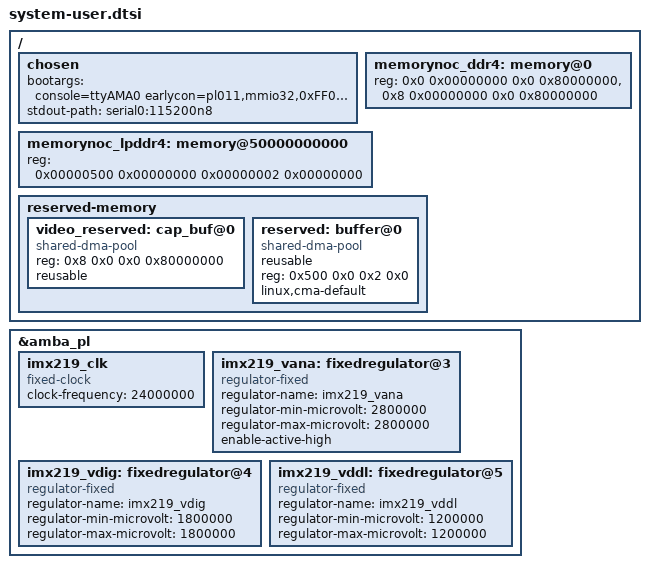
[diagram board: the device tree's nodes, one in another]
//#include <dt-bindings/media/xilinx-vip.h>
/include/ "system-conf.dtsi"
/ {
	chosen {
		//bootargs = "console=ttyAMA0  earlycon=pl011,mmio32,0xFF000000,115200n8 clk_ignore_unused root=/dev/mmcblk0p2 rw rootwait";	
		//bootargs = "console=ttyAMA0  earlycon=pl011,mmio32,0xFF000000,115200n8 clk_ignore_unused debug root=/dev/mmcblk0p2 rw rootwait";
		//bootargs = "console=ttyAMA0  earlycon=pl011,mmio32,0xFF000000,115200n8 clk_ignore_unused dyndbg=\"QUERY\" root=/dev/mmcblk0p2 rw rootwait";
		bootargs = "console=ttyAMA0  earlycon=pl011,mmio32,0xFF000000,115200n8 clk_ignore_unused dyndbg=\"file drivers/gpu/drm/xlnx/* +p\" root=/dev/mmcblk0p2 rw rootwait";
		stdout-path = "serial0:115200n8";
	};

	memorynoc_ddr4: memory@0 {
		device_type = "memory";
		reg = <0x0 0x00000000 0x0 0x80000000>, <0x8 0x00000000 0x0 0x80000000>;
	};

	memorynoc_lpddr4: memory@50000000000 {
		device_type = "memory";
		reg = <0x00000500 0x00000000 0x00000002 0x00000000>;
	};

	reserved-memory {
		#address-cells = <2>;
		#size-cells = <2>;
		ranges;

		video_reserved: cap_buf@0 {
			compatible = "shared-dma-pool";
			reg = <0x8 0x0 0x0 0x80000000>;
			reusable;
		};

		reserved: buffer@0 {
			compatible = "shared-dma-pool";
			reusable;
			reg = <0x500 0x0 0x2 0x0>;
			linux,cma-default;
		};
	};
};

#include "i2c0_mux_conf.dtsi"

&amba_pl {
	imx219_clk: imx219_clk {
		#clock-cells = <0x0>;
		clock-frequency = <24000000>;
		compatible = "fixed-clock";
	};

	imx219_vana: fixedregulator@3 {
		compatible = "regulator-fixed";
		regulator-name = "imx219_vana";
		regulator-min-microvolt = <2800000>;
		regulator-max-microvolt = <2800000>;
		enable-active-high;
	};

	imx219_vdig: fixedregulator@4 {
		compatible = "regulator-fixed";
		regulator-name = "imx219_vdig";
		regulator-min-microvolt = <1800000>;
		regulator-max-microvolt = <1800000>;
	};

	imx219_vddl: fixedregulator@5 {
		compatible = "regulator-fixed";
		regulator-name = "imx219_vddl";
		regulator-min-microvolt = <1200000>;
		regulator-max-microvolt = <1200000>;
	};		

};



#include "pl-custom.dtsi"
#include "mipi-0-imx219.dtsi"
#include "mipi-1-imx219.dtsi"
#include "mipi-3-imx219.dtsi"
#include "display.dtsi"









